# STM32WLE4xx register map
File version: 1.0
Registers are 32-bit, read-write, reset 0x0 unless marked. A register's access mark holds for its fields unless they carry their own. Offsets are from the block's base; [hi:lo] are bit positions; {n}, {i} and the like mark numbered series.

## PKA — Public Key Accelerator (PKA)
Base 0x58002000
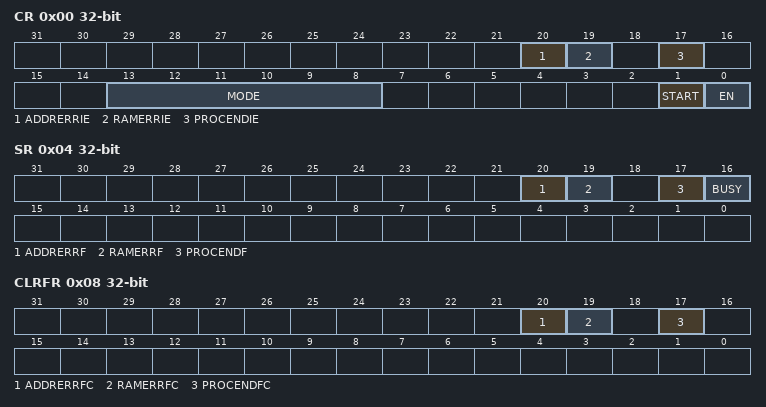
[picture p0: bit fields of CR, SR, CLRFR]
0x00 CR — PKA control register
  [20] ADDRERRIE — RAM error interrupt enable
  [19] RAMERRIE — RAM error interrupt enable
  [17] PROCENDIE — End of operation interrupt enable
  [13:8] MODE — MODE[5:0] PKA operation code
  [1] START — Start operation
  [0] EN — PKA enable
0x04 SR — PKA status register
  [20] ADDRERRF — Address error flag
  [19] RAMERRF — PKA RAM error flag
  [17] PROCENDF — PKA end of operation flag
  [16] BUSY — PKA operation is in progress
0x08 CLRFR — PKA clear flag register
  [20] ADDRERRFC — Clear address error flag
  [19] RAMERRFC — Clear PKA RAM error flag
  [17] PROCENDFC — Clear PKA end of operation flag
{0x400+4i} RAM[{i}] (i=0..893)

## FLASH — FLASH Registers
Base 0x58004000
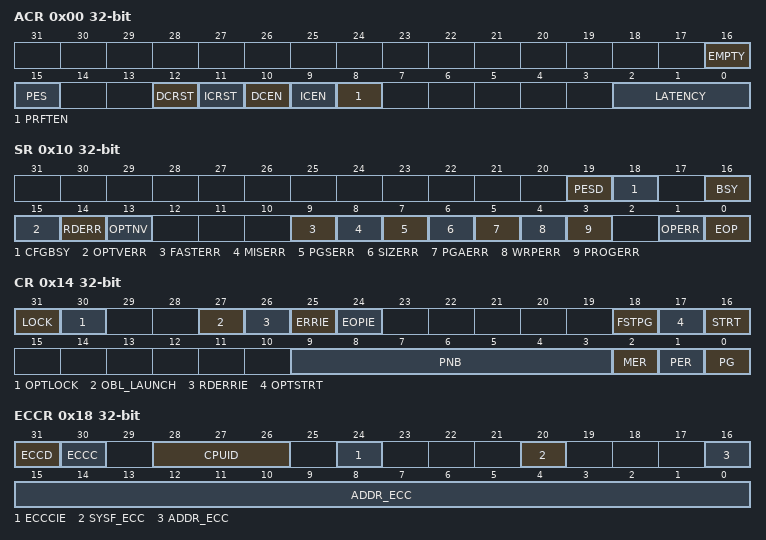
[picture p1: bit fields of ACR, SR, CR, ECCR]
0x00 ACR — FLASH Access control register
  [16] EMPTY — Flash use area empty
  [15] PES — Program/erase suspend request
  [12] DCRST — Data cache reset
  [11] ICRST — Instruction cache reset
  [10] DCEN — Data cache enable
  [9] ICEN — Instruction cache enable
  [8] PRFTEN — Prefetch enable
  [2:0] LATENCY
    0=FLASH Zero wait state; 1=FLASH One wait state; 2=FLASH Two wait states
0x08 KEYR — FLASH Key register
0x0C OPTKEYR — FLASH Option Key register
0x10 SR — FLASH Status register
  [19] PESD — Programming/erase operation suspended
  [18] CFGBSY — Programming or erase configuration busy
  [16] BSY — Flash Busy
  [15] OPTVERR — Option validity error
  [14] RDERR — PCROP read error
  [13] OPTNV — User option OPTVAL indication
  [9] FASTERR — Fast programming error
  [8] MISERR — Fast programming data miss error
  [7] PGSERR — Programming sequence error
  [6] SIZERR — Size error
  [5] PGAERR — Programming alignment error
  [4] WRPERR — Write protection error
  [3] PROGERR — Programming error
  [1] OPERR — Operation error
  [0] EOP — End of Operation
0x14 CR — FLASH Control register
  [31] LOCK — Flash control register lock
  [30] OPTLOCK — Options lock
  [27] OBL_LAUNCH — Force the option bute loading
  [26] RDERRIE — PCROP read error interrupt enable
  [25] ERRIE — Error interrupt enable
  [24] EOPIE — End of operation interrupt enable
  [18] FSTPG — Fast programming
  [17] OPTSTRT — Options modification start
  [16] STRT — Start an erase operation
  [9:3] PNB — Page number selection mask
  [2] MER — Mass erase
  [1] PER — Page erase
  [0] PG — Flash programming
0x18 ECCR — FLASH ECC register
  [31] ECCD — ECC detection
  [30] ECCC — ECC correction
  [28:26] CPUID — CPU identification
  [24] ECCCIE — ECC correction interrupt enable
  [20] SYSF_ECC — System flash ECC fail
  [16:0] ADDR_ECC — double-word address ECC fail
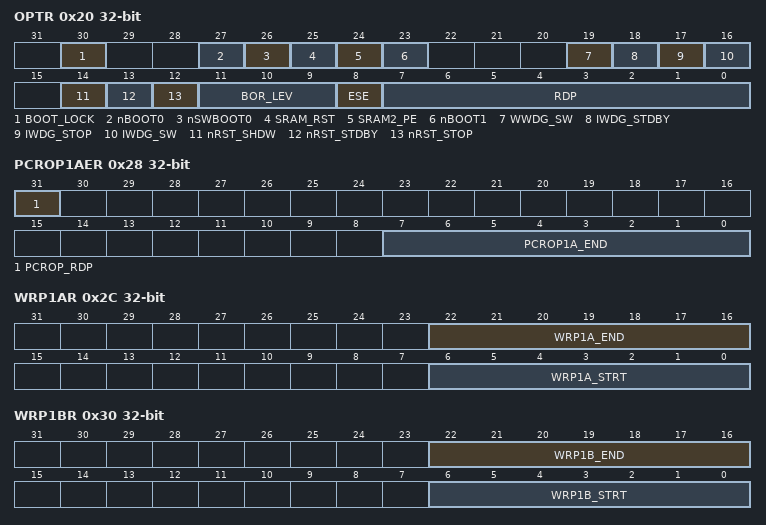
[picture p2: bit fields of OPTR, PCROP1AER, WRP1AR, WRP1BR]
0x20 OPTR — FLASH Option register
  [30] BOOT_LOCK — CPU1 Boot Lock enable option bit
  [27] nBOOT0 — BOOT0 option bit
  [26] nSWBOOT0 — Software BOOT0
  [25] SRAM_RST — SRAM1 and SRAM2 erase option when system reset
  [24] SRAM2_PE — SRAM2 parity check enable
  [23] nBOOT1 — Boot Configuration
  [19] WWDG_SW — Window watchdog selection
  [18] IWDG_STDBY — Independent watchdog counter option in Standby mode
  [17] IWDG_STOP — Independent watchdog counter option in Stop mode
  [16] IWDG_SW — Independent watchdog selection
  [14] nRST_SHDW — Reset option in Shutdown mode
  [13] nRST_STDBY — Reset option in Standby mode
  [12] nRST_STOP — Reset option in Stop mode
  [11:9] BOR_LEV — BOR reset level mask
  [8] ESE — Security enable
  [7:0] RDP — Read protection level
0x24 PCROP1ASR — FLASH Bank 1 PCROP area A Start address register
  [7:0] PCROP1A_STRT — PCROP area A start offset
0x28 PCROP1AER — FLASH Bank 1 PCROP area A End address register
  [31] PCROP_RDP — PCROP area preserved when RDP level decreased
  [7:0] PCROP1A_END — PCROP area A end offset
0x2C WRP1AR — FLASH Bank 1 WRP area A address register
  [22:16] WRP1A_END — WRP area A end offset
  [6:0] WRP1A_STRT — WRP area A start offset
0x30 WRP1BR — FLASH Bank 1 WRP area B address register
  [22:16] WRP1B_END — WRP area B end offset
  [6:0] WRP1B_STRT — WRP area B start offset
0x34 PCROP1BSR — FLASH Bank 1 PCROP area B Start address register
  [7:0] PCROP1B_STRT — PCROP area B start offset
0x38 PCROP1BER — FLASH Bank 1 PCROP area B End address register
  [7:0] PCROP1B_END — PCROP area B end offset

## DBGMCU — Debug MCU
Base 0xE0042000
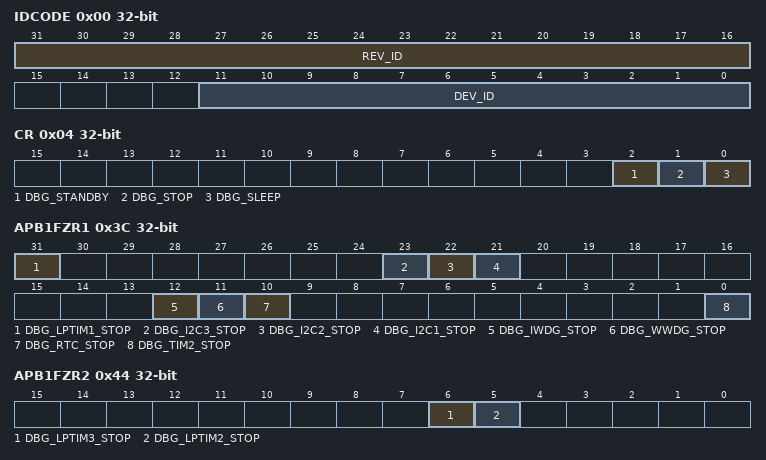
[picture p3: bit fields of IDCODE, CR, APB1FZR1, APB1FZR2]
0x00 IDCODE — MCU device ID code
  [31:16] REV_ID, [11:0] DEV_ID
0x04 CR — Debug MCU configuration register
  [2] DBG_STANDBY, [1] DBG_STOP, [0] DBG_SLEEP
0x3C APB1FZR1 — Debug MCU CPU1 APB1 freeze register
  [31] DBG_LPTIM1_STOP, [23] DBG_I2C3_STOP, [22] DBG_I2C2_STOP, [21] DBG_I2C1_STOP, [12] DBG_IWDG_STOP, [11] DBG_WWDG_STOP, [10] DBG_RTC_STOP, [0] DBG_TIM2_STOP
0x44 APB1FZR2 — Debug MCU CPU1 APB1 freeze register
  [6] DBG_LPTIM3_STOP, [5] DBG_LPTIM2_STOP
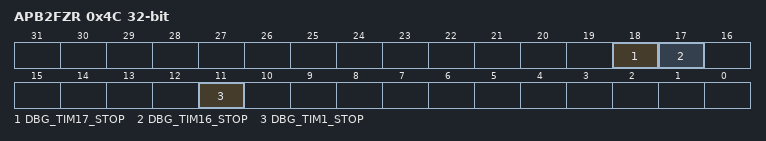
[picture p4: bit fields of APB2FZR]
0x4C APB2FZR — Debug MCU CPU1 APB2 freeze register
  [18] DBG_TIM17_STOP, [17] DBG_TIM16_STOP, [11] DBG_TIM1_STOP
